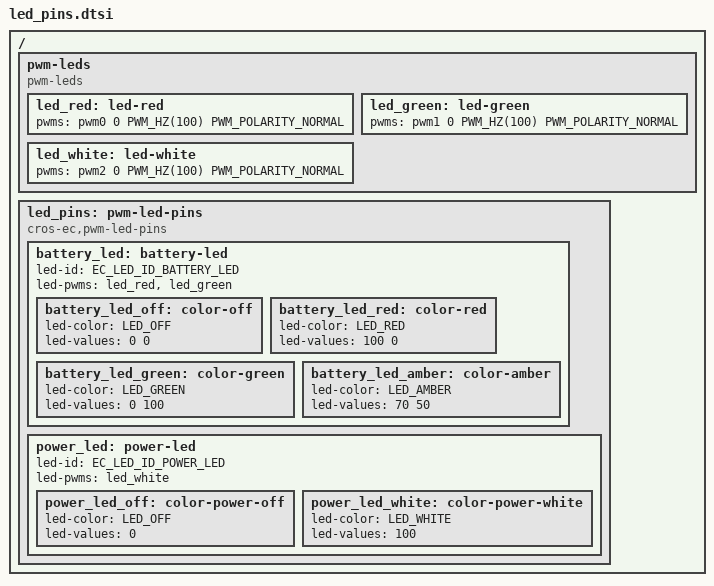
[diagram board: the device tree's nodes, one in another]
/* Copyright 2025 The ChromiumOS Authors
 * Use of this source code is governed by a BSD-style license that can be
 * found in the LICENSE file.
 */

 / {
	pwm-leds {
		compatible = "pwm-leds";
		led_red: led-red {
			pwms = <&pwm0 0 PWM_HZ(100) PWM_POLARITY_NORMAL>;
		};
		led_green: led-green {
			pwms = <&pwm1 0 PWM_HZ(100) PWM_POLARITY_NORMAL>;
		};
		led_white: led-white {
			pwms = <&pwm2 0 PWM_HZ(100) PWM_POLARITY_NORMAL>;
		};
	};

	led_pins: pwm-led-pins {
		compatible = "cros-ec,pwm-led-pins";

		battery_led: battery-led {
			led-id = "EC_LED_ID_BATTERY_LED";
			led-pwms = <&led_red &led_green>;
			battery_led_off: color-off {
				led-color = "LED_OFF";
				led-values = <0 0>;
			};

			battery_led_red: color-red {
				led-color = "LED_RED";
				led-values = <100 0>;
			};

			battery_led_green: color-green {
				led-color = "LED_GREEN";
				led-values = <0 100>;
			};

			battery_led_amber: color-amber {
				led-color = "LED_AMBER";
				led-values = <70 50>;
			};
		};

		power_led: power-led {
			led-id = "EC_LED_ID_POWER_LED";
			led-pwms = <&led_white>;

			power_led_off: color-power-off {
				led-color = "LED_OFF";
				led-values = <0>;
			};

			power_led_white: color-power-white {
				led-color = "LED_WHITE";
				led-values = <100>;
			};
		};
	};
};
